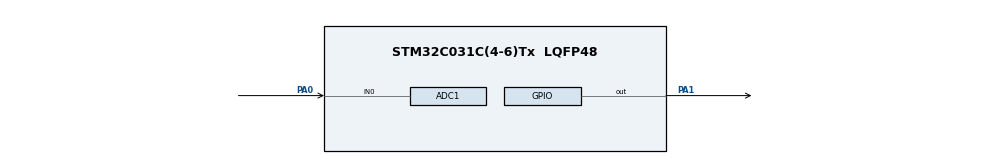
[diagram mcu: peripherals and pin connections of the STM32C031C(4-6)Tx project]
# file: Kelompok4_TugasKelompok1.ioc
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ADC1.ClockPrescaler=ADC_CLOCK_SYNC_PCLK_DIV4
ADC1.NbrOfConversionFlag=0
ADC1.SamplingTimeCommon1=ADC_SAMPLETIME_160CYCLES_5
ADC1.SelectedChannel=ADC_CHANNEL_0
ADC1.master=1
Mcu.Family=STM32C0
Mcu.Name=STM32C031C(4-6)Tx
Mcu.Package=LQFP48
PA0.Mode=IN0
PA0.Signal=ADC1_IN0
PA1.Signal=GPIO_Output
ProjectManager.HeapSize=0x200
ProjectManager.StackSize=0x400
ProjectManager.TargetToolchain=STM32CubeIDE
RCC.ADCFreq_Value=12000000
RCC.AHBFreq_Value=12000000
RCC.CortexFreq_Value=12000000
RCC.EXTERNAL_CLOCK_VALUE=12288000
RCC.HCLKFreq_Value=12000000
RCC.HSE_VALUE=8000000
RCC.HSI_VALUE=48000000
RCC.LSE_VALUE=32768
RCC.SYSCLKFreq_VALUE=12000000
board=custom

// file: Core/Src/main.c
/* USER CODE BEGIN Header */
/**
  ******************************************************************************
  * @file           : main.c
  * @brief          : Main program body
  ******************************************************************************
  * @attention
  *
  * Copyright (c) 2025 STMicroelectronics.
  * All rights reserved.
  *
  * This software is licensed under terms that can be found in the LICENSE file
  * in the root directory of this software component.
  * If no LICENSE file comes with this software, it is provided AS-IS.
  *
  ******************************************************************************
  */
/* USER CODE END Header */
#include "main.h"

/* USER CODE BEGIN Includes */
#include <math.h>
/* USER CODE END Includes */

/* USER CODE BEGIN PD */
#define INTERVAL 1000
#define LED_PIN GPIO_PIN_1
#define R0 10000.0f
#define T0 298.15f // 25 C dalam Kelvin
#define BETA 3950.0f
#define R_FIXED 10000.0f // Nilai resistor tetap
/* USER CODE END PD */

ADC_HandleTypeDef hadc1;

void SystemClock_Config(void);
static void MX_GPIO_Init(void);
static void MX_ADC1_Init(void);

int main(void)
{

  /* MCU Configuration--------------------------------------------------------*/

  /* Reset of all peripherals, Initializes the Flash interface and the Systick. */
  HAL_Init();

  /* Configure the system clock */
  SystemClock_Config();

  /* Initialize all configured peripherals */
  MX_GPIO_Init();
  MX_ADC1_Init();
  /* USER CODE BEGIN 2 */
  uint32_t previousMillis = 0, currentMillis;
  uint16_t ntcAdcValue = 0;
  float voltageNtc, resistanceNtc, tempKelvin, tempCelsius;
  /* USER CODE END 2 */

  /* Infinite loop */
  /* USER CODE BEGIN WHILE */
  while (1) {
    currentMillis = HAL_GetTick();
    if (currentMillis - previousMillis >= INTERVAL) {
      previousMillis = currentMillis;

      HAL_ADC_Start(&hadc1);
      HAL_ADC_PollForConversion(&hadc1, HAL_MAX_DELAY);
      ntcAdcValue = HAL_ADC_GetValue(&hadc1);
      HAL_ADC_Stop(&hadc1);

      // Konversi data digital ke suhu
      voltageNtc = (float)ntcAdcValue / 4095.0f * 3.3f;
      resistanceNtc = R_FIXED * (voltageNtc / (3.3f - voltageNtc));
      tempKelvin = 1.0f / ((1.0f / T0) + (1.0f / BETA) * logf(resistanceNtc / R0));
      tempCelsius = (tempKelvin - 273.15f);

      if (tempCelsius >= 50) {
        HAL_GPIO_WritePin(GPIOA, LED_PIN, GPIO_PIN_SET);
      } else {
        HAL_GPIO_WritePin(GPIOA, LED_PIN, GPIO_PIN_RESET);
      }
    }
    /* USER CODE END WHILE */

  }
}

void SystemClock_Config(void)
{
  RCC_OscInitTypeDef RCC_OscInitStruct = {0};
  RCC_ClkInitTypeDef RCC_ClkInitStruct = {0};

  __HAL_FLASH_SET_LATENCY(FLASH_LATENCY_0);

  /** Initializes the RCC Oscillators according to the specified parameters
  * in the RCC_OscInitTypeDef structure.
  */
  RCC_OscInitStruct.OscillatorType = RCC_OSCILLATORTYPE_HSI;
  RCC_OscInitStruct.HSIState = RCC_HSI_ON;
  RCC_OscInitStruct.HSIDiv = RCC_HSI_DIV4;
  RCC_OscInitStruct.HSICalibrationValue = RCC_HSICALIBRATION_DEFAULT;
  if (HAL_RCC_OscConfig(&RCC_OscInitStruct) != HAL_OK)
  {
    Error_Handler();
  }

  /** Initializes the CPU, AHB and APB buses clocks
  */
  RCC_ClkInitStruct.ClockType = RCC_CLOCKTYPE_HCLK|RCC_CLOCKTYPE_SYSCLK
                              |RCC_CLOCKTYPE_PCLK1;
  RCC_ClkInitStruct.SYSCLKSource = RCC_SYSCLKSOURCE_HSI;
  RCC_ClkInitStruct.SYSCLKDivider = RCC_SYSCLK_DIV1;
  RCC_ClkInitStruct.AHBCLKDivider = RCC_HCLK_DIV1;
  RCC_ClkInitStruct.APB1CLKDivider = RCC_APB1_DIV1;

  if (HAL_RCC_ClockConfig(&RCC_ClkInitStruct, FLASH_LATENCY_0) != HAL_OK)
  {
    Error_Handler();
  }
}

static void MX_ADC1_Init(void)
{

  ADC_ChannelConfTypeDef sConfig = {0};

  /** Configure the global features of the ADC (Clock, Resolution, Data Alignment and number of conversion)
  */
  hadc1.Instance = ADC1;
  hadc1.Init.ClockPrescaler = ADC_CLOCK_SYNC_PCLK_DIV4;
  hadc1.Init.Resolution = ADC_RESOLUTION_12B;
  hadc1.Init.DataAlign = ADC_DATAALIGN_RIGHT;
  hadc1.Init.ScanConvMode = ADC_SCAN_SEQ_FIXED;
  hadc1.Init.EOCSelection = ADC_EOC_SINGLE_CONV;
  hadc1.Init.LowPowerAutoWait = DISABLE;
  hadc1.Init.LowPowerAutoPowerOff = DISABLE;
  hadc1.Init.ContinuousConvMode = DISABLE;
  hadc1.Init.NbrOfConversion = 1;
  hadc1.Init.DiscontinuousConvMode = DISABLE;
  hadc1.Init.ExternalTrigConv = ADC_SOFTWARE_START;
  hadc1.Init.ExternalTrigConvEdge = ADC_EXTERNALTRIGCONVEDGE_NONE;
  hadc1.Init.DMAContinuousRequests = DISABLE;
  hadc1.Init.Overrun = ADC_OVR_DATA_PRESERVED;
  hadc1.Init.SamplingTimeCommon1 = ADC_SAMPLETIME_160CYCLES_5;
  hadc1.Init.OversamplingMode = DISABLE;
  hadc1.Init.TriggerFrequencyMode = ADC_TRIGGER_FREQ_HIGH;
  if (HAL_ADC_Init(&hadc1) != HAL_OK)
  {
    Error_Handler();
  }

  /** Configure Regular Channel
  */
  sConfig.Channel = ADC_CHANNEL_0;
  sConfig.Rank = ADC_RANK_CHANNEL_NUMBER;
  if (HAL_ADC_ConfigChannel(&hadc1, &sConfig) != HAL_OK)
  {
    Error_Handler();
  }

}

static void MX_GPIO_Init(void)
{
  GPIO_InitTypeDef GPIO_InitStruct = {0};

  /* GPIO Ports Clock Enable */
  __HAL_RCC_GPIOA_CLK_ENABLE();

  /*Configure GPIO pin Output Level */
  HAL_GPIO_WritePin(GPIOA, GPIO_PIN_1, GPIO_PIN_RESET);

  /*Configure GPIO pin : PA1 */
  GPIO_InitStruct.Pin = GPIO_PIN_1;
  GPIO_InitStruct.Mode = GPIO_MODE_OUTPUT_PP;
  GPIO_InitStruct.Pull = GPIO_NOPULL;
  GPIO_InitStruct.Speed = GPIO_SPEED_FREQ_LOW;
  HAL_GPIO_Init(GPIOA, &GPIO_InitStruct);

}

void Error_Handler(void)
{
  __disable_irq();
  while (1)
  {
  }
}
